# pse84_a0 register map
Vendor: Infineon Technologies; Series: PSE84_A0; File version: 1.0
CPU: CM33 r0p1, little endian, MPU, FPU, VTOR, 3 interrupt priority bits
Registers are 32-bit, read-write, reset 0x0 unless marked. A register's access mark holds for its fields unless they carry their own. Offsets are from the block's base; [hi:lo] are bit positions; lines under a group give offsets from that group.

## GFXSS (part 1 of 4)
Base 0x44800000
0x00 GFXSS_GPU group — Graphics Processing Unit.
  0x00 MXGPU group — Platform IP standard configuration for GPU.
    0x00 CTL — IP control.
      [31] ENABLED — IP enable bit. When disabled (value 0), the functional state of the GCNano core is reset and its clock input gated. Access to MMIO of the core results in an AHB error response. Note, that the effect of this bit is delayed (see STATUS.CORE_RST). The core must be idle (no outstanding or pending AXI transactions) before clearing this bit.
    0x0C STATUS ro reset 0x1 — IP status.
      [0] CORE_RST — Reset state of the GCNano core (1 = in reset). This state is delayed to GFXSS_GPU reset. After reset de-activation it has to be checked for value 0 before the core can be used. After activation it has to be checked for value 1 before turning off the external clk_hf source.
    0x10 INTR — Interrupt status bits.
      [0] CORE — GCNanoLiteV core has signalled an interrupt. Writing a '1' to this field will reset the bit. Interrupt stats inside the core is not affected by this.
    0x14 INTR_SET — Interrupt set bits.
      [0] CORE_SET — Write this field with '1' to set corresponding INTR field (a write of '0' has no effect).
    0x18 INTR_MASK — Interrupt mask bits.
      [0] CORE_MASK — Mask for corresponding field in INTR register.
    0x1C INTR_MASKED ro — Interrupt masked bits.
      [0] CORE_MASKED — Logical AND of corresponding INTR and INTR_MASK fields.
  0x800 GCNANO group — Host Interface Registers
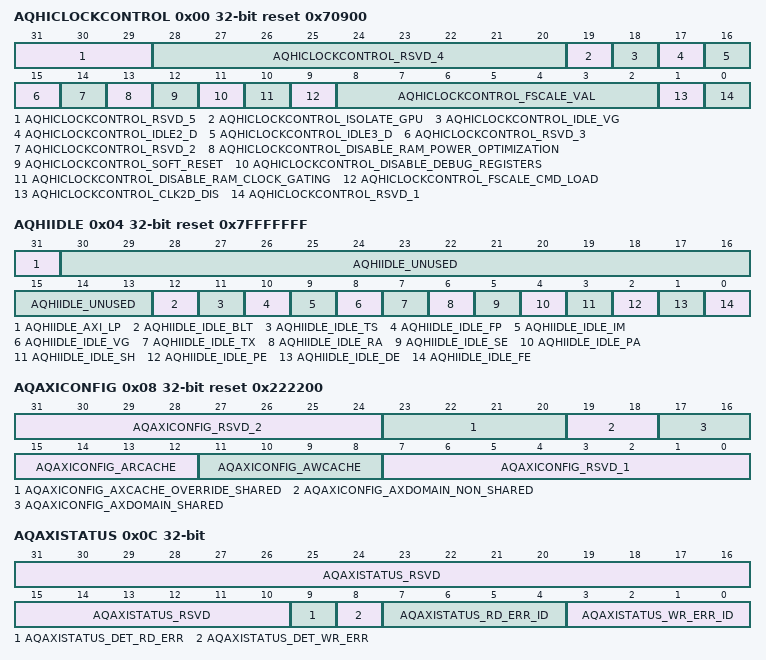
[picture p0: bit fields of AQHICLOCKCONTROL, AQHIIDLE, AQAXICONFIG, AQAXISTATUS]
    0x00 AQHICLOCKCONTROL reset 0x70900 — Clock Control Register.
      [31:29] AQHICLOCKCONTROL_RSVD_5 ro
      [28:20] AQHICLOCKCONTROL_RSVD_4
      [19] AQHICLOCKCONTROL_ISOLATE_GPU — Isolate GPU bit, used for power on/power off.
      [18] AQHICLOCKCONTROL_IDLE_VG ro — VG pipe is idle.
      [17] AQHICLOCKCONTROL_IDLE2_D ro — 2D pipe is idle or not present.
      [16] AQHICLOCKCONTROL_IDLE3_D ro — 3D pipe is idle or not present.
      [15] AQHICLOCKCONTROL_RSVD_3 ro
      [14] AQHICLOCKCONTROL_RSVD_2
      [13] AQHICLOCKCONTROL_DISABLE_RAM_POWER_OPTIMIZATION — Disables ram power optimization.
      [12] AQHICLOCKCONTROL_SOFT_RESET — Soft resets the IP.
      [11] AQHICLOCKCONTROL_DISABLE_DEBUG_REGISTERS — Disable debug registers. If this bit is 1, debug registers are clock gated.
      [10] AQHICLOCKCONTROL_DISABLE_RAM_CLOCK_GATING — Disables clock gating for rams.
      [9] AQHICLOCKCONTROL_FSCALE_CMD_LOAD — Core clock frequency scale value enable. When writing a 1 to this bit, it updates the frequency scale factor with the value FSCALE_VAL[6:0]. The bit must be set back to 0 after that. If this bit is set and FSCALE_VAL=0 (an invalid combination), the HREADYOUT output signal will get stuck to 0.
      [8:2] AQHICLOCKCONTROL_FSCALE_VAL — Core clock frequency scale value.
      [1] AQHICLOCKCONTROL_CLK2D_DIS — Disable 2D/VG clock. CLK2D_DIS should be controlled by software. The AXI interface clock is the only block not stalled at that point.
      [0] AQHICLOCKCONTROL_RSVD_1
    0x04 AQHIIDLE ro reset 0x7FFFFFFF — Idle Status Register.
      [31] AQHIIDLE_AXI_LP — AXI is in low power mode.
      [30:13] AQHIIDLE_UNUSED
      [12] AQHIIDLE_IDLE_BLT — BLT is idle or not present.
      [11] AQHIIDLE_IDLE_TS — TS (Tessellation Engine): 1=TS is idle.
      [10] AQHIIDLE_IDLE_FP — FP is idle or not present.
      [9] AQHIIDLE_IDLE_IM — IM (Image Engine): 1= IM is idle.
      [8] AQHIIDLE_IDLE_VG — VG (Vector Graphics Engine): 1= VG is idle.
      [7] AQHIIDLE_IDLE_TX — TX is idle or not present.
      [6] AQHIIDLE_IDLE_RA — RA is idle or not present.
      [5] AQHIIDLE_IDLE_SE — SE is idle or not present.
      [4] AQHIIDLE_IDLE_PA — PA is idle or not present.
      [3] AQHIIDLE_IDLE_SH — SH is idle or not present.
      [2] AQHIIDLE_IDLE_PE — PE (Pixel Engine): 1-PE is idle.
      [1] AQHIIDLE_IDLE_DE — DE is idle or not present.
      [0] AQHIIDLE_IDLE_FE — FE (Fetch Engine): 0=FE is busy; 1=FE is idle.
    0x08 AQAXICONFIG reset 0x222200 — AXI Configuration Register.
      [31:24] AQAXICONFIG_RSVD_2 ro
      [23:20] AQAXICONFIG_AXCACHE_OVERRIDE_SHARED — Configure AxCACHE value for shareable request. Not used for VG cores
      [19:18] AQAXICONFIG_AXDOMAIN_NON_SHARED — Configure AxDOMAIN value for non-shareable request. Not used for VG cores
      [17:16] AQAXICONFIG_AXDOMAIN_SHARED — Configure AxDOMAIN value for shareable request. Not used for VG cores
      [15:12] AQAXICONFIG_ARCACHE — Set ARCACHE[3:0] value.
      [11:8] AQAXICONFIG_AWCACHE — Set AWCACHE[3:0] value.
      [7:0] AQAXICONFIG_RSVD_1
    0x0C AQAXISTATUS ro — AXI Status Register. READ ONLY. Back-to-back read is forbidden to this register and can cause system hang. Please insert delay (nop operation) between two consecutive reads while accessing this register outside of VSI drivers.
      [31:10] AQAXISTATUS_RSVD
      [9] AQAXISTATUS_DET_RD_ERR — 1=A read error is detected.
      [8] AQAXISTATUS_DET_WR_ERR — 1=A write error is detected.
      [7:4] AQAXISTATUS_RD_ERR_ID — The ID which caused illegal read access error.
      [3:0] AQAXISTATUS_WR_ERR_ID — The ID which caused illegal write access error.
    0x10 AQINTRACKNOWLEDGE ro — Interrupt Acknowledge Register. Each bit represents a corresponding event being triggered. Reading from this register clears the outstanding interrupt. READ ONLY. When the access comes from a debugger (HMASTER[0] == 1), the clear by read function is disabled. Back-to-back read is forbidden to this register and can cause system hang. Please insert delay (nop operation) between two consecutive reads while accessing this register outside of VSI drivers.
      [31:0] AQINTRACKNOWLEDGE_INTR_VEC — For each interrupt event, 0=Clear, 1=Interrupt Active. For all cores: Bit 31 is AXI_BUS_ERROR. 0=No error, 1=Interrupt Active.
    0x14 AQINTRENBL — Interrupt Enable Register. Each bit enables a corresponding event.
      [31:0] AQINTRENBL_INTR_ENBL_VEC — 0=Disable Interrupt; 1=Enable interrupt.
    0x24 GCCHIPREV ro reset not defined — Chip Revsion Register. Shows the revision for the chip in BCD. This register has no set reset value. It varies with the implementation. READ ONLY.
      [31:0] GCCHIPREV_REV — Revision. This value may vary between releases and can be ignored during test.
    0x28 GCCHIPDATE ro reset not defined — Chip Date Register. Shows the release date for the IP in YYYYMMDD (year/month/day) format. This register has no set reset value. It varies with the implementation. READ ONLY.
      [31:0] GCCHIPDATE_DATE — Date. This value will vary each release and can be ignored during test.
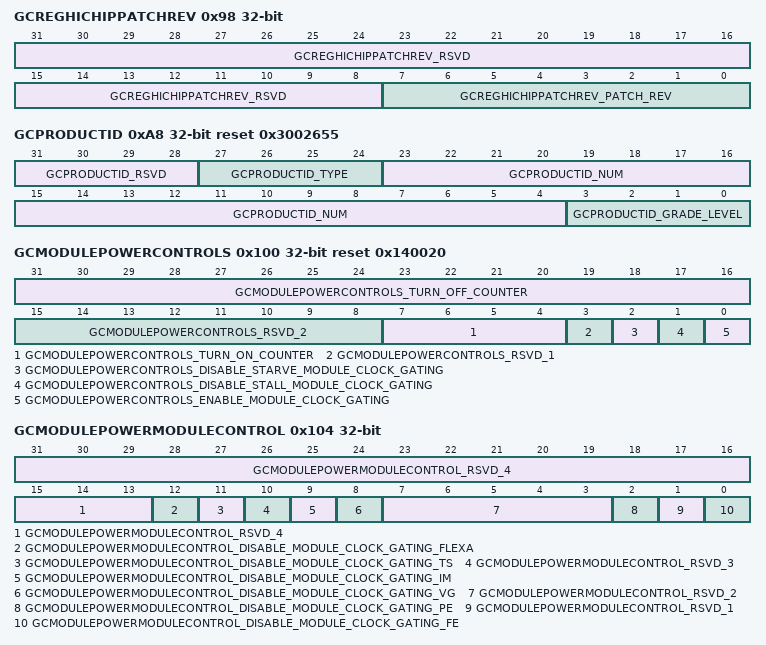
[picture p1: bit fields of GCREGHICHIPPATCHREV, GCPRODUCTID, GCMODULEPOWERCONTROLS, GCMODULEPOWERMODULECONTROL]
    0x98 GCREGHICHIPPATCHREV ro (reset mask 0xFFFFFF00) — Chip Patch Revision Register. Patch revision level for the chip. It varies per release. READ ONLY
      [31:8] GCREGHICHIPPATCHREV_RSVD
      [7:0] GCREGHICHIPPATCHREV_PATCH_REV — Patch Revision. This value will vary each release and can be ignored during test.
    0xA8 GCPRODUCTID ro reset 0x3002655 — Product Identification Register. Shows Product ID. READ ONLY.
      [31:28] GCPRODUCTID_RSVD
      [27:24] GCPRODUCTID_TYPE — Product Type is 3: VG (Vector Graphics).
      [23:4] GCPRODUCTID_NUM — Product number is 265.
      [3:0] GCPRODUCTID_GRADE_LEVEL — 0:None-no extra letter on the product name for this core; 1:Nano; 5:NanoUltra.
    0x100 GCMODULEPOWERCONTROLS reset 0x140020 — Module Power Control Register. Control register for module level power controls.
      [31:16] GCMODULEPOWERCONTROLS_TURN_OFF_COUNTER — Counter value for clock gating the module if the module is idle for this amount of clock cycles.
      [15:8] GCMODULEPOWERCONTROLS_RSVD_2 ro
      [7:4] GCMODULEPOWERCONTROLS_TURN_ON_COUNTER — Number of clock cycles to wait after turning on the clock.
      [3] GCMODULEPOWERCONTROLS_RSVD_1 ro
      [2] GCMODULEPOWERCONTROLS_DISABLE_STARVE_MODULE_CLOCK_GATING — Disables module level clock gating for starve/idle condition.
      [1] GCMODULEPOWERCONTROLS_DISABLE_STALL_MODULE_CLOCK_GATING — Disables module level clock gating for stall condition.
      [0] GCMODULEPOWERCONTROLS_ENABLE_MODULE_CLOCK_GATING — Enables module level clock gating.
    0x104 GCMODULEPOWERMODULECONTROL — Module Power Module Control Register. Module level control register.
      [31:13] GCMODULEPOWERMODULECONTROL_RSVD_4 ro
      [12] GCMODULEPOWERMODULECONTROL_DISABLE_MODULE_CLOCK_GATING_FLEXA ro — Disables module level clock gating for Flexa. Not supported for all variants.
      [11] GCMODULEPOWERMODULECONTROL_DISABLE_MODULE_CLOCK_GATING_TS — Disables module level clock gating for TS.
      [10] GCMODULEPOWERMODULECONTROL_RSVD_3
      [9] GCMODULEPOWERMODULECONTROL_DISABLE_MODULE_CLOCK_GATING_IM — Disables module level clock gating for IM.
      [8] GCMODULEPOWERMODULECONTROL_DISABLE_MODULE_CLOCK_GATING_VG — Disables module level clock gating for VG.
      [7:3] GCMODULEPOWERMODULECONTROL_RSVD_2
      [2] GCMODULEPOWERMODULECONTROL_DISABLE_MODULE_CLOCK_GATING_PE — Disables module level clock gating for PE.
      [1] GCMODULEPOWERMODULECONTROL_RSVD_1
      [0] GCMODULEPOWERMODULECONTROL_DISABLE_MODULE_CLOCK_GATING_FE — Disables module level clock gating for FE.
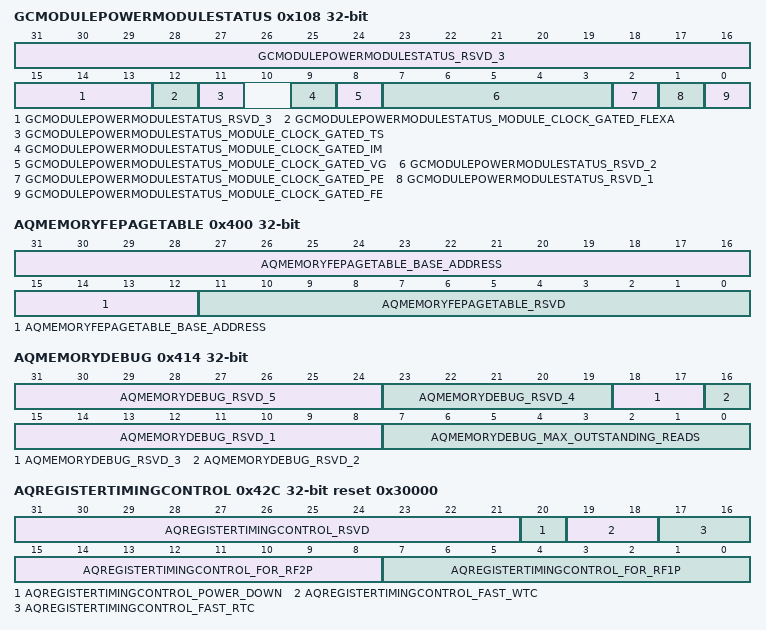
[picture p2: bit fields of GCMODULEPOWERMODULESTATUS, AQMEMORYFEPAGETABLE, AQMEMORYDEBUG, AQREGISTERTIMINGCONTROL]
    0x108 GCMODULEPOWERMODULESTATUS ro — Module Power Module Status Register. Module level control status.
      [31:13] GCMODULEPOWERMODULESTATUS_RSVD_3
      [12] GCMODULEPOWERMODULESTATUS_MODULE_CLOCK_GATED_FLEXA — Module level clock gating is ON for Flexa. Not supported for all variants.
      [11] GCMODULEPOWERMODULESTATUS_MODULE_CLOCK_GATED_TS — Module level clock gating is ON for TS.
      [9] GCMODULEPOWERMODULESTATUS_MODULE_CLOCK_GATED_IM — Module level clock gating is ON for IM.
      [8] GCMODULEPOWERMODULESTATUS_MODULE_CLOCK_GATED_VG — Module level clock gating is ON for VG.
      [7:3] GCMODULEPOWERMODULESTATUS_RSVD_2
      [2] GCMODULEPOWERMODULESTATUS_MODULE_CLOCK_GATED_PE — Module level clock gating is ON for PE.
      [1] GCMODULEPOWERMODULESTATUS_RSVD_1
      [0] GCMODULEPOWERMODULESTATUS_MODULE_CLOCK_GATED_FE — Module level clock gating is ON for FE.
    0x400 AQMEMORYFEPAGETABLE — Fetch Engine Page Table Base Address Register.
      [31:12] AQMEMORYFEPAGETABLE_BASE_ADDRESS — Base address for the FE virtual address lookup table.
      [11:0] AQMEMORYFEPAGETABLE_RSVD ro
    0x414 AQMEMORYDEBUG — Memory Debug Register.
      [31:24] AQMEMORYDEBUG_RSVD_5 ro
      [23:19] AQMEMORYDEBUG_RSVD_4
      [18:17] AQMEMORYDEBUG_RSVD_3 ro
      [16] AQMEMORYDEBUG_RSVD_2
      [15:8] AQMEMORYDEBUG_RSVD_1 ro
      [7:0] AQMEMORYDEBUG_MAX_OUTSTANDING_READS — Limits the total number of outstanding read requests.
    0x42C AQREGISTERTIMINGCONTROL reset 0x30000 — Timing Control Register.
      [31:21] AQREGISTERTIMINGCONTROL_RSVD
      [20] AQREGISTERTIMINGCONTROL_POWER_DOWN — Powerdown memory.
      [19:18] AQREGISTERTIMINGCONTROL_FAST_WTC — WTC for fast rams.
      [17:16] AQREGISTERTIMINGCONTROL_FAST_RTC — RTC for fast rams.
      [15:8] AQREGISTERTIMINGCONTROL_FOR_RF2P — For 2 port ram.
      [7:0] AQREGISTERTIMINGCONTROL_FOR_RF1P — For 1 port ram.
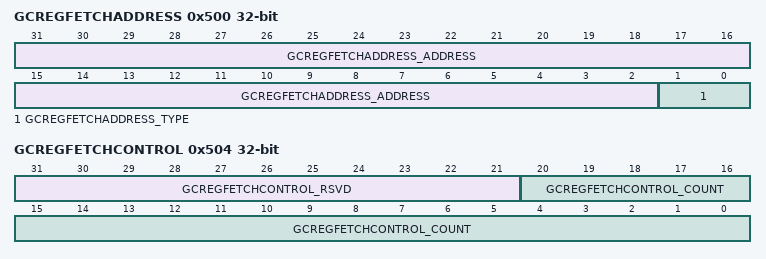
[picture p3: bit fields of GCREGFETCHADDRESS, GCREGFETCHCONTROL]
    0x500 GCREGFETCHADDRESS — Fetch Command Buffer Base Address Register. Address of the command buffer. The address must be 64-byte aligned.
      [31:2] GCREGFETCHADDRESS_ADDRESS — fetch address
      [1:0] GCREGFETCHADDRESS_TYPE
        0=SYSTEM ((none)); 2=VIRTUAL ((none)); 1=LOCAL ((none))
    0x504 GCREGFETCHCONTROL — Fetch Control Register. Writing a non-zero value to this register starts the fetch engine. The FE will start fetching 64-bit commands and data starting at the address specified by the gcregFetchAddress register. Make sure this count is large enough to fetch the END command, otherwise the FE will wait until more data is coming.
      [31:21] GCREGFETCHCONTROL_RSVD ro
      [20:0] GCREGFETCHCONTROL_COUNT — Number of 64-bit words to fetch. 21 bits is enough for 16 MB.
    0x508 GCREGCURRENTFETCHADDRESS ro — Current Fetch Command Address Register. Debugging register that defines the current address the FE is fetching data from. READ ONLY.
      [31:0] GCREGCURRENTFETCHADDRESS_ADDRESS — (none)
